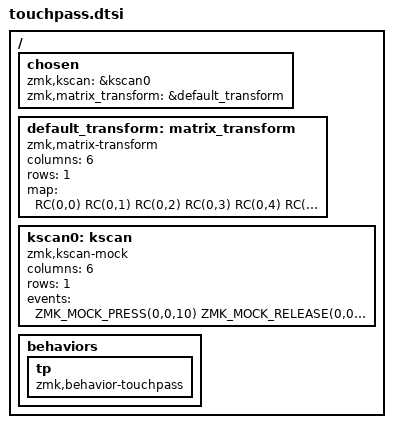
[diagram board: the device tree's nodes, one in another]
#include <dt-bindings/zmk/matrix_transform.h>

/ {
    chosen {
        zmk,kscan = &kscan0;
        zmk,matrix_transform = &default_transform;
    };


    default_transform: matrix_transform {
        compatible = "zmk,matrix-transform";
        columns = <6>;
        rows = <1>;
        map = <RC(0,0) RC(0,1) RC(0,2) RC(0,3) RC(0,4) RC(0,5)>;
    };
#include <dt-bindings/zmk/kscan_mock.h>

    kscan0: kscan {
        compatible = "zmk,kscan-mock";
        status = "okay";
        columns = <6>;
        rows = <1>;
        events = <ZMK_MOCK_PRESS(0,0,10) ZMK_MOCK_RELEASE(0,0,10)>;
    };

    behaviors {
        tp: tp {
            compatible = "zmk,behavior-touchpass";
            #binding-cells = <0>;
        };
    };
};
